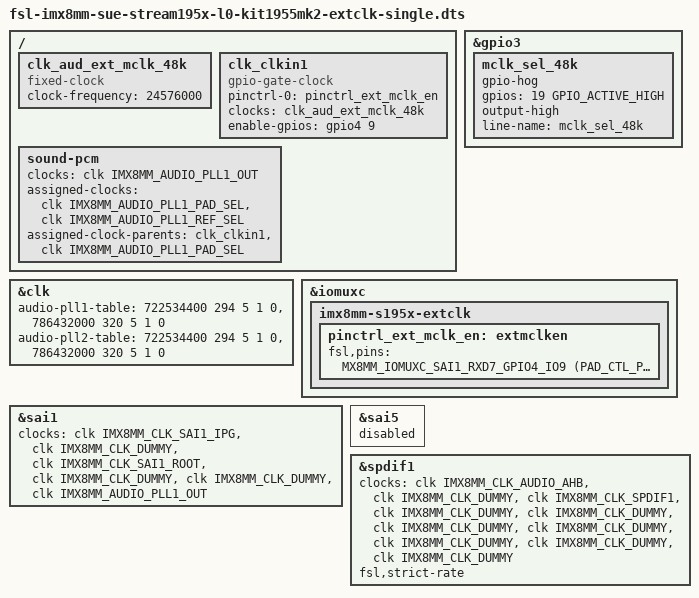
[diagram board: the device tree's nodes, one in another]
/dts-v1/;

#include "fsl-imx8mm-sue-stream195x-internal.dtsi"
#include "fsl-imx8mm-sue-stream195x-kit1955.dtsi"
#include "fsl-imx8mm-sue-stream195x-kit1955-override-mk2.dtsi"
#include "fsl-imx8mm-sue-stream195x-kit-lcd.dtsi"
#include "fsl-imx8mm-sue-stream195x-kit1955-touchscreen.dtsi"

/ {
	clk_aud_ext_mclk_48k: clk_aud_ext_mclk_48k {
		compatible = "fixed-clock";
		#clock-cells = <0>;
		clock-frequency = <24576000>;
	};

	// NOTE: The name of the node must be `clk_clkin1` matching the entry
	//       in the `clk_pad_sels[]` list in `clk-imx8mm.c`.
	clk_clkin1: clk_clkin1 {
		compatible = "gpio-gate-clock";
		#clock-cells = <0>;

		pinctrl-names = "default";
		pinctrl-0 = <&pinctrl_ext_mclk_en>;

		clocks = <&clk_aud_ext_mclk_48k>;
		enable-gpios = <&gpio4 9 GPIO_ACTIVE_HIGH>;
	};

	sound-pcm {
		// Remove `pll11k` clock as we ony use PLL1 (pll8k) which will provide both
		// rates derived from the CLKIN1 clock.
		clocks = <&clk IMX8MM_AUDIO_PLL1_OUT>;
		clock-names = "pll8k";

		// This sets the parent of the PLL1 to the clk_clkin1 clock.
		assigned-clocks = <&clk IMX8MM_AUDIO_PLL1_PAD_SEL>, <&clk IMX8MM_AUDIO_PLL1_REF_SEL>;
		assigned-clock-parents = <&clk_clkin1>, <&clk IMX8MM_AUDIO_PLL1_PAD_SEL>;
	};
};

&clk {
	// Table when using a single external 24.576 MHz osciallator on CLKIN1.
	// If the CLKIN1 input has a different frequency this table needs to be updated.
	audio-pll1-table = <722534400 294 5 1 0>,	// For 44.1 kHz
			   <786432000 320 5 1 0>;	// For 48 kHz

	// TODO: Also populate the PLL2 table so that we don't get an
	// spurious error message during the boot.
	audio-pll2-table = <722534400 294 5 1 0>,	// For 44.1 kHz
			   <786432000 320 5 1 0>;	// For 48 kHz
};

&gpio3 {
	// NOTE: This is so that we get the 24.576 MHz clock on our highend configuration as
	//       the PLL tables above are calculated for this input rate.
	mclk_sel_48k {
		gpio-hog;
		gpios = <19 GPIO_ACTIVE_HIGH>;
		output-high;
		line-name = "mclk_sel_48k";
	};
};

&iomuxc {
	imx8mm-s195x-extclk {
		pinctrl_ext_mclk_en: extmclken {
			fsl,pins = <
				MX8MM_IOMUXC_SAI1_RXD7_GPIO4_IO9	(PAD_CTL_PE_DOWN)
			>;
		};
	};
};

&sai1 {
	// This removes the `pll11k` entry from the list, so the SAI driver
	// will not reparent to a different PLL and all rates will be using
	// PLL1.
	clocks = <&clk IMX8MM_CLK_SAI1_IPG>, <&clk IMX8MM_CLK_DUMMY>,
		 <&clk IMX8MM_CLK_SAI1_ROOT>,
		 <&clk IMX8MM_CLK_DUMMY>, <&clk IMX8MM_CLK_DUMMY>,
		 <&clk IMX8MM_AUDIO_PLL1_OUT>;
	clock-names = "bus", "mclk0", "mclk1", "mclk2", "mclk3",
		      "pll8k";
};

// Disable the SAI5 to not have a pin conflict with `MX8MM_IOMUXC_SAI5_RXFS_GPIO3_IO19`, the
// SAI5 is used for a microphone input which we do not use in this configuration.
&sai5 {
	status = "disabled";
};

&spdif1 {
	// Changes:
	// 1. Remove the `pll8k` and `pll11k` clocks: This ensures that the driver will
	//    not try to reparent the `spdif1` clock to a different PLL and instead the
	//    `spdif1` clock will always be under the `pll1` clock.
	// 2. Set all `rxtx<n>` clocks to the dummy clock except `rxtx1`. Togehter with
	//    the `fsl,strict-rate` flag below, the driver will only allow playback if
	//    requested sample-rate can be cleanly derived from the `pll1` to the `spdif1`
	//    clock.
	clocks = <&clk IMX8MM_CLK_AUDIO_AHB>, <&clk IMX8MM_CLK_DUMMY>,
		<&clk IMX8MM_CLK_SPDIF1>, <&clk IMX8MM_CLK_DUMMY>,
		<&clk IMX8MM_CLK_DUMMY>, <&clk IMX8MM_CLK_DUMMY>,
		<&clk IMX8MM_CLK_DUMMY>, <&clk IMX8MM_CLK_DUMMY>,
		<&clk IMX8MM_CLK_DUMMY>, <&clk IMX8MM_CLK_DUMMY>;

	clock-names = "core", "rxtx0", "rxtx1", "rxtx2", "rxtx3",
		"rxtx4", "rxtx5", "rxtx6", "rxtx7", "spba";

	// Setting this flag prevents playback if internally the desired playback rate
	// cannot be cleanly divided from the provided clocks (in our case only the `spdif1`
	// clock is available).
	fsl,strict-rate;
};
